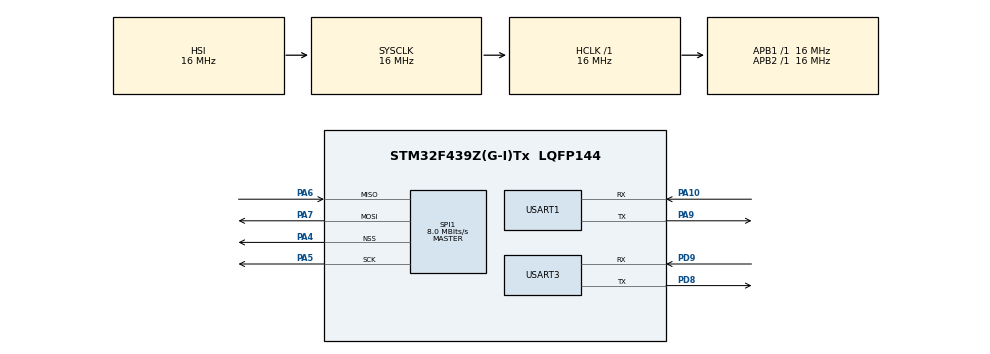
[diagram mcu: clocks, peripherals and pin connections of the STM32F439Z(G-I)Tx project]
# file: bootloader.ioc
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Dma.Request0=SPI1_RX
Dma.Request1=SPI1_TX
Dma.SPI1_RX.0.Direction=DMA_PERIPH_TO_MEMORY
Dma.SPI1_RX.0.FIFOMode=DMA_FIFOMODE_DISABLE
Dma.SPI1_RX.0.Instance=DMA2_Stream0
Dma.SPI1_RX.0.MemDataAlignment=DMA_MDATAALIGN_BYTE
Dma.SPI1_RX.0.MemInc=DMA_MINC_ENABLE
Dma.SPI1_RX.0.Mode=DMA_NORMAL
Dma.SPI1_RX.0.PeriphDataAlignment=DMA_PDATAALIGN_BYTE
Dma.SPI1_RX.0.PeriphInc=DMA_PINC_DISABLE
Dma.SPI1_RX.0.Priority=DMA_PRIORITY_LOW
Dma.SPI1_TX.1.Direction=DMA_MEMORY_TO_PERIPH
Dma.SPI1_TX.1.FIFOMode=DMA_FIFOMODE_DISABLE
Dma.SPI1_TX.1.Instance=DMA2_Stream3
Dma.SPI1_TX.1.MemDataAlignment=DMA_MDATAALIGN_BYTE
Dma.SPI1_TX.1.MemInc=DMA_MINC_ENABLE
Dma.SPI1_TX.1.Mode=DMA_NORMAL
Dma.SPI1_TX.1.PeriphDataAlignment=DMA_PDATAALIGN_BYTE
Dma.SPI1_TX.1.PeriphInc=DMA_PINC_DISABLE
Dma.SPI1_TX.1.Priority=DMA_PRIORITY_LOW
Mcu.Family=STM32F4
Mcu.Name=STM32F439Z(G-I)Tx
Mcu.Package=LQFP144
NVIC.DMA2_Stream0_IRQn=true\:0\:0\:false\:false\:true\:false\:true
NVIC.DMA2_Stream3_IRQn=true\:0\:0\:false\:false\:true\:false\:true
NVIC.PriorityGroup=NVIC_PRIORITYGROUP_4
PA10.Mode=Asynchronous
PA10.Signal=USART1_RX
PA4.Mode=NSS_Signal_Hard_Output
PA4.Signal=SPI1_NSS
PA5.Mode=Full_Duplex_Master
PA5.Signal=SPI1_SCK
PA6.Mode=Full_Duplex_Master
PA6.Signal=SPI1_MISO
PA7.Mode=Full_Duplex_Master
PA7.Signal=SPI1_MOSI
PA9.Mode=Asynchronous
PA9.Signal=USART1_TX
PC14/OSC32_IN.Mode=LSE-External-Oscillator
PC14/OSC32_IN.Signal=RCC_OSC32_IN
PC15/OSC32_OUT.Mode=LSE-External-Oscillator
PC15/OSC32_OUT.Signal=RCC_OSC32_OUT
PD8.Mode=Asynchronous
PD8.Signal=USART3_TX
PD9.Mode=Asynchronous
PD9.Signal=USART3_RX
ProjectManager.HeapSize=0x200
ProjectManager.StackSize=0x400
ProjectManager.TargetToolchain=STM32CubeIDE
RCC.AHBFreq_Value=16000000
RCC.APB1Freq_Value=16000000
RCC.APB2Freq_Value=16000000
RCC.CortexFreq_Value=16000000
RCC.HSE_VALUE=25000000
RCC.HSI_VALUE=16000000
RCC.SYSCLKFreq_VALUE=16000000
RCC.VCOOutputFreq_Value=192000000
SPI1.CalculateBaudRate=8.0 MBits/s
SPI1.Direction=SPI_DIRECTION_2LINES
SPI1.Mode=SPI_MODE_MASTER
SPI1.VirtualNSS=VM_NSSHARD
SPI1.VirtualType=VM_MASTER
USART1.VirtualMode=VM_ASYNC
USART3.VirtualMode=VM_ASYNC
board=custom

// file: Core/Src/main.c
/* USER CODE BEGIN Header */
/**
  ******************************************************************************
  * @file           : main.c
  * @brief          : Main program body
  ******************************************************************************
  * @attention
  *
  * <h2><center>&copy; Copyright (c) 2020 STMicroelectronics.
  * All rights reserved.</center></h2>
  *
  * This software component is licensed by ST under BSD 3-Clause license,
  * the "License"; You may not use this file except in compliance with the
  * License. You may obtain a copy of the License at:
  *                        opensource.org/licenses/BSD-3-Clause
  *
  ******************************************************************************
  */
/* USER CODE END Header */

#include "main.h"

/* USER CODE BEGIN Includes */
#include "bootloader.h"
/* USER CODE END Includes */

SPI_HandleTypeDef hspi1;
DMA_HandleTypeDef hdma_spi1_rx;
DMA_HandleTypeDef hdma_spi1_tx;

UART_HandleTypeDef huart1;
UART_HandleTypeDef huart3;

void SystemClock_Config(void);
static void MX_GPIO_Init(void);
static void MX_DMA_Init(void);
static void MX_USART3_UART_Init(void);
static void MX_SPI1_Init(void);
static void MX_USART1_UART_Init(void);

int main(void)
{

  /* MCU Configuration--------------------------------------------------------*/

  /* Reset of all peripherals, Initializes the Flash interface and the Systick. */
  HAL_Init();

  /* Configure the system clock */
  SystemClock_Config();

  /* Initialize all configured peripherals */
  MX_GPIO_Init();
  MX_DMA_Init();
  MX_USART3_UART_Init();
  MX_SPI1_Init();
  MX_USART1_UART_Init();
  /* USER CODE BEGIN 2 */

 // NVIC_EnableIRQ(USART3_IRQn);

    // __HAL_UART_ENABLE_IT(&huart3,UART_IT_RXNE);

  /* USER CODE END 2 */

  /* Infinite loop */
  /* USER CODE BEGIN WHILE */
  printf("%s():- Entry\n", __FUNCTION__);

  BOOTLOADER_Start();

  while (1)
  {
    /* USER CODE END WHILE */

  }
}

void SystemClock_Config(void)
{
  RCC_OscInitTypeDef RCC_OscInitStruct = {0};
  RCC_ClkInitTypeDef RCC_ClkInitStruct = {0};

  /** Configure the main internal regulator output voltage
  */
  __HAL_RCC_PWR_CLK_ENABLE();
  __HAL_PWR_VOLTAGESCALING_CONFIG(PWR_REGULATOR_VOLTAGE_SCALE3);
  /** Initializes the CPU, AHB and APB busses clocks
  */
  RCC_OscInitStruct.OscillatorType = RCC_OSCILLATORTYPE_HSI;
  RCC_OscInitStruct.HSIState = RCC_HSI_ON;
  RCC_OscInitStruct.HSICalibrationValue = RCC_HSICALIBRATION_DEFAULT;
  RCC_OscInitStruct.PLL.PLLState = RCC_PLL_NONE;
  if (HAL_RCC_OscConfig(&RCC_OscInitStruct) != HAL_OK)
  {
    Error_Handler();
  }
  /** Initializes the CPU, AHB and APB busses clocks
  */
  RCC_ClkInitStruct.ClockType = RCC_CLOCKTYPE_HCLK|RCC_CLOCKTYPE_SYSCLK
                              |RCC_CLOCKTYPE_PCLK1|RCC_CLOCKTYPE_PCLK2;
  RCC_ClkInitStruct.SYSCLKSource = RCC_SYSCLKSOURCE_HSI;
  RCC_ClkInitStruct.AHBCLKDivider = RCC_SYSCLK_DIV1;
  RCC_ClkInitStruct.APB1CLKDivider = RCC_HCLK_DIV1;
  RCC_ClkInitStruct.APB2CLKDivider = RCC_HCLK_DIV1;

  if (HAL_RCC_ClockConfig(&RCC_ClkInitStruct, FLASH_LATENCY_0) != HAL_OK)
  {
    Error_Handler();
  }
}

static void MX_SPI1_Init(void)
{

  /* SPI1 parameter configuration*/
  hspi1.Instance = SPI1;
  hspi1.Init.Mode = SPI_MODE_MASTER;
  hspi1.Init.Direction = SPI_DIRECTION_2LINES;
  hspi1.Init.DataSize = SPI_DATASIZE_8BIT;
  hspi1.Init.CLKPolarity = SPI_POLARITY_LOW;
  hspi1.Init.CLKPhase = SPI_PHASE_1EDGE;
  hspi1.Init.NSS = SPI_NSS_HARD_OUTPUT;
  hspi1.Init.BaudRatePrescaler = SPI_BAUDRATEPRESCALER_2;
  hspi1.Init.FirstBit = SPI_FIRSTBIT_MSB;
  hspi1.Init.TIMode = SPI_TIMODE_DISABLE;
  hspi1.Init.CRCCalculation = SPI_CRCCALCULATION_DISABLE;
  hspi1.Init.CRCPolynomial = 10;
  if (HAL_SPI_Init(&hspi1) != HAL_OK)
  {
    Error_Handler();
  }

}

static void MX_USART1_UART_Init(void)
{

  huart1.Instance = USART1;
  huart1.Init.BaudRate = 115200;
  huart1.Init.WordLength = UART_WORDLENGTH_8B;
  huart1.Init.StopBits = UART_STOPBITS_1;
  huart1.Init.Parity = UART_PARITY_NONE;
  huart1.Init.Mode = UART_MODE_TX_RX;
  huart1.Init.HwFlowCtl = UART_HWCONTROL_NONE;
  huart1.Init.OverSampling = UART_OVERSAMPLING_16;
  if (HAL_UART_Init(&huart1) != HAL_OK)
  {
    Error_Handler();
  }

}

static void MX_USART3_UART_Init(void)
{

  huart3.Instance = USART3;
  huart3.Init.BaudRate = 115200;
  huart3.Init.WordLength = UART_WORDLENGTH_8B;
  huart3.Init.StopBits = UART_STOPBITS_1;
  huart3.Init.Parity = UART_PARITY_NONE;
  huart3.Init.Mode = UART_MODE_TX_RX;
  huart3.Init.HwFlowCtl = UART_HWCONTROL_NONE;
  huart3.Init.OverSampling = UART_OVERSAMPLING_16;
  if (HAL_UART_Init(&huart3) != HAL_OK)
  {
    Error_Handler();
  }

}

static void MX_DMA_Init(void)
{

  /* DMA controller clock enable */
  __HAL_RCC_DMA2_CLK_ENABLE();

  /* DMA interrupt init */
  /* DMA2_Stream0_IRQn interrupt configuration */
  HAL_NVIC_SetPriority(DMA2_Stream0_IRQn, 0, 0);
  HAL_NVIC_EnableIRQ(DMA2_Stream0_IRQn);
  /* DMA2_Stream3_IRQn interrupt configuration */
  HAL_NVIC_SetPriority(DMA2_Stream3_IRQn, 0, 0);
  HAL_NVIC_EnableIRQ(DMA2_Stream3_IRQn);

}

static void MX_GPIO_Init(void)
{

  /* GPIO Ports Clock Enable */
  __HAL_RCC_GPIOC_CLK_ENABLE();
  __HAL_RCC_GPIOA_CLK_ENABLE();
  __HAL_RCC_GPIOD_CLK_ENABLE();

}

/* USER CODE BEGIN 4 */
#if 0
int __io_putchar(int ch) {
  HAL_UART_Transmit(&huart3, (uint8_t *)&ch, 1, 0xFFFF);
  return ch;
}
#endif

/* USER CODE END 4 */

void Error_Handler(void)
{
}

/************************ (C) COPYRIGHT STMicroelectronics *****END OF FILE****/
